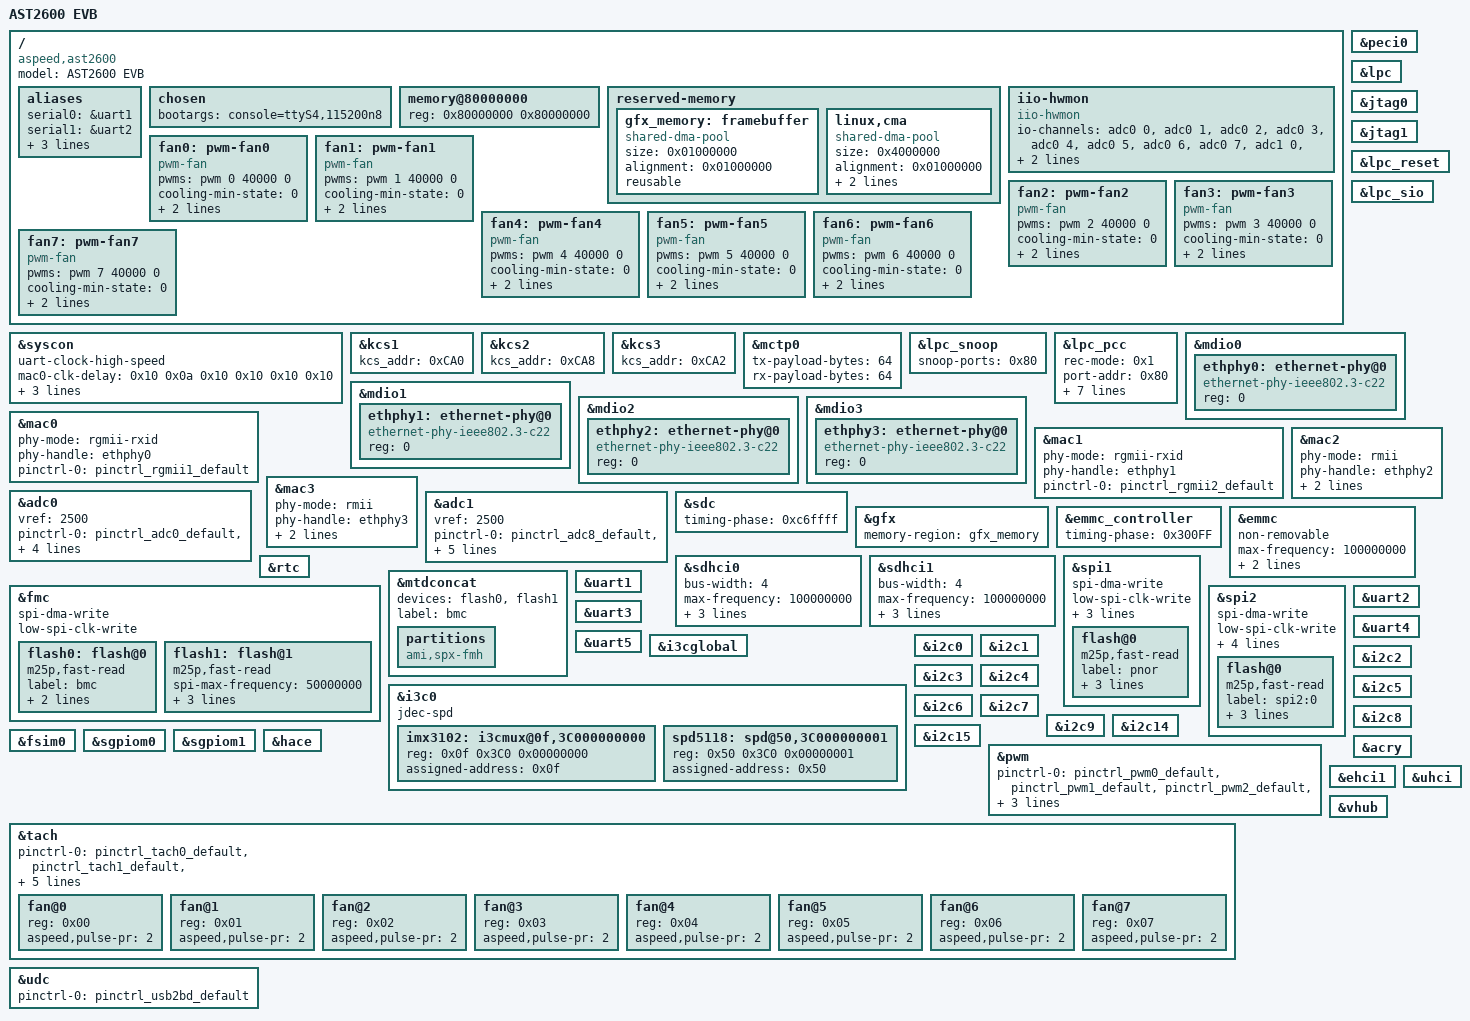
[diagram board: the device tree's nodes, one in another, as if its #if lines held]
// SPDX-License-Identifier: GPL-2.0-or-later
// Copyright 2019 IBM Corp.

/dts-v1/;

#include "aspeed-g6.dtsi"
#include <dt-bindings/gpio/aspeed-gpio.h>
#include <dt-bindings/i2c/i2c.h>
#include "../../../../../../include/projdef.h"

/ {
	model = "AST2600 EVB";
	compatible = "aspeed,ast2600";

	aliases {
		serial0 = &uart1;
		serial1 = &uart2;
		serial2 = &uart3;
		serial3 = &uart4;
		serial4 = &uart5;
	};

	chosen {
		bootargs = "console=ttyS4,115200n8";
	};

	memory@80000000 {
		device_type = "memory";
		reg = <0x80000000 0x80000000>;
	};
        reserved-memory {
                #address-cells = <1>;
                #size-cells = <1>;
                ranges;

                gfx_memory: framebuffer {
                        size = <0x01000000>;
                        alignment = <0x01000000>;
                        compatible = "shared-dma-pool";
                        reusable;
                };
#if defined(CONFIG_SPX_FEATURE_VIDEO_RVAS)
                linux,cma {
			            size = <0x4000000>; //64MB
			            alignment = <0x01000000>;
			            compatible = "shared-dma-pool";
			            reusable;
			            linux,cma-default;
                };
#endif				
         };



    iio-hwmon {
        compatible = "iio-hwmon";
        io-channels = <&adc0 0>, <&adc0 1>, <&adc0 2>, <&adc0 3>,
                        <&adc0 4>, <&adc0 5>, <&adc0 6>, <&adc0 7>,
                        <&adc1 0>, <&adc1 1>, <&adc1 2>, <&adc1 3>,
                        <&adc1 4>, <&adc1 5>, <&adc1 6>, <&adc1 7>;
    };

	fan0: pwm-fan0 {
		compatible = "pwm-fan";
		pwms = <&pwm 0 40000 0>;	/* Target freq:25 kHz */
		cooling-min-state = <0>;
		cooling-max-state = <3>;
		#cooling-cells = <2>;
		cooling-levels = <0 25 128 255>;
	};

	fan1: pwm-fan1 {
		compatible = "pwm-fan";
		pwms = <&pwm 1 40000 0>;	/* Target freq:25 kHz */
		cooling-min-state = <0>;
		cooling-max-state = <3>;
		#cooling-cells = <2>;
		cooling-levels = <0 15 128 255>;
	};

	fan2: pwm-fan2 {
		compatible = "pwm-fan";
		pwms = <&pwm 2 40000 0>;	/* Target freq:25 kHz */
		cooling-min-state = <0>;
		cooling-max-state = <3>;
		#cooling-cells = <2>;
		cooling-levels = <0 15 128 255>;
	};

	fan3: pwm-fan3 {
		compatible = "pwm-fan";
		pwms = <&pwm 3 40000 0>;	/* Target freq:25 kHz */
		cooling-min-state = <0>;
		cooling-max-state = <3>;
		#cooling-cells = <2>;
		cooling-levels = <0 15 128 255>;
	};

	fan4: pwm-fan4 {
		compatible = "pwm-fan";
		pwms = <&pwm 4 40000 0>;	/* Target freq:25 kHz */
		cooling-min-state = <0>;
		cooling-max-state = <3>;
		#cooling-cells = <2>;
		cooling-levels = <0 15 128 255>;
	};

	fan5: pwm-fan5 {
		compatible = "pwm-fan";
		pwms = <&pwm 5 40000 0>;	/* Target freq:25 kHz */
		cooling-min-state = <0>;
		cooling-max-state = <3>;
		#cooling-cells = <2>;
		cooling-levels = <0 15 128 255>;
	};

	fan6: pwm-fan6 {
		compatible = "pwm-fan";
		pwms = <&pwm 6 40000 0>;	/* Target freq:25 kHz */
		cooling-min-state = <0>;
		cooling-max-state = <3>;
		#cooling-cells = <2>;
		cooling-levels = <0 15 128 255>;
	};

	fan7: pwm-fan7 {
		compatible = "pwm-fan";
		pwms = <&pwm 7 40000 0>;	/* Target freq:25 kHz */
		cooling-min-state = <0>;
		cooling-max-state = <3>;
		#cooling-cells = <2>;
		cooling-levels = <0 15 128 255>;
	};
};

&syscon {
        uart-clock-high-speed;
        status = "okay";
		
		mac0-clk-delay = <0x10 0x0a
				  0x10 0x10
				  0x10 0x10>;
		mac1-clk-delay = <0x10 0x0a
				  0x10 0x10
				  0x10 0x10>;
		mac2-clk-delay = <0x08 0x04
				  0x08 0x04
				  0x08 0x04>;
		mac3-clk-delay = <0x08 0x04
				  0x08 0x04
				  0x08 0x04>;		
};

&kcs1 {
        kcs_addr = <0xCA0>;
        status = "okay";
};

&kcs2 {
        kcs_addr = <0xCA8>;
        status = "okay";
};

&kcs3 {
        kcs_addr = <0xCA2>;
        status = "okay";
};

&peci0 {
    status = "okay";
};

&lpc {
    status = "okay";
};

&jtag0 {
        status = "okay";
};

&jtag1 {
        status = "okay";
};

&mctp0 {
    tx-payload-bytes= <64>;
    rx-payload-bytes= <64>;
    status = "okay";
};

&lpc_reset {
        status = "okay";
};

&lpc_sio {
        status = "okay";
};

&lpc_snoop {
        snoop-ports = <0x80>;
        status = "okay";
};

&lpc_pcc { 
	rec-mode = <0x1>; 
	port-addr = <0x80>; 
	port-addr-hbits-select = <0x1>; 
	port-addr-xbits = <0x1>; 
	pattern-a-en; 
	pattern-a = <0x41424344>; 
	pattern-a-len = <0x4>; 
	pattern-a-write = <0x1>; 
	pattern-a-port = <0x80>; 
	status = "okay"; 
};

&mdio0 {
        status = "okay";

        ethphy0: ethernet-phy@0 {
                compatible = "ethernet-phy-ieee802.3-c22";
                reg = <0>;
        };
};

&mdio1 {
	status = "okay";

	ethphy1: ethernet-phy@0 {
		compatible = "ethernet-phy-ieee802.3-c22";
		reg = <0>;
	};
};

&mdio2 {
	status = "okay";

	ethphy2: ethernet-phy@0 {
		compatible = "ethernet-phy-ieee802.3-c22";
		reg = <0>;
	};
};

&mdio3 {
	status = "okay";

	ethphy3: ethernet-phy@0 {
		compatible = "ethernet-phy-ieee802.3-c22";
		reg = <0>;
	};
};

&mac0 {
        status = "okay";

        phy-mode = "rgmii-rxid";
        phy-handle = <&ethphy0>;

        pinctrl-names = "default";
        pinctrl-0 = <&pinctrl_rgmii1_default>;
};

&mac1 {
	status = "okay";

	phy-mode = "rgmii-rxid";
	phy-handle = <&ethphy1>;

	pinctrl-names = "default";
	pinctrl-0 = <&pinctrl_rgmii2_default>;
};

#ifdef CONFIG_SPX_FEATURE_NCSI_ACTIVE_MAC3
&mac2 {
	status = "okay";

	phy-mode = "rmii";
	phy-handle = <&ethphy2>;
	use-ncsi;
	
	pinctrl-names = "default";
	pinctrl-0 = <&pinctrl_rmii3_default>;
};
#else
&mac2 {
	status = "okay";

	phy-mode = "rgmii";
	phy-handle = <&ethphy2>;
	
	pinctrl-names = "default";
	pinctrl-0 = <&pinctrl_rgmii3_default>;
};
#endif

#ifdef CONFIG_SPX_FEATURE_NCSI_ACTIVE_MAC4
&mac3 {
	status = "okay";

	phy-mode = "rmii";
	phy-handle = <&ethphy3>;
	use-ncsi;
	
	pinctrl-names = "default";
	pinctrl-0 = <&pinctrl_rmii4_default>;
};
#else
&mac3 {
	status = "okay";

	phy-mode = "rgmii";
	phy-handle = <&ethphy3>;

	pinctrl-names = "default";
	pinctrl-0 = <&pinctrl_rgmii4_default>;
};
#endif

&adc0 {
	vref = <2500>;
	status = "okay";

	pinctrl-names = "default";
	pinctrl-0 = <&pinctrl_adc0_default &pinctrl_adc1_default
		&pinctrl_adc2_default &pinctrl_adc3_default
		&pinctrl_adc4_default &pinctrl_adc5_default
		&pinctrl_adc6_default &pinctrl_adc7_default>;
};

&adc1 {
	vref = <2500>;
	status = "okay";

	pinctrl-names = "default";
	pinctrl-0 = <&pinctrl_adc8_default &pinctrl_adc9_default
		&pinctrl_adc10_default &pinctrl_adc11_default
		&pinctrl_adc12_default &pinctrl_adc13_default
		&pinctrl_adc14_default &pinctrl_adc15_default>;
};

&sdc {
	status = "okay";	
};

&gfx {
        status = "okay";
        memory-region = <&gfx_memory>;
};

&emmc_controller {
	status = "okay";
	timing-phase = <0x300FF>;
};

&emmc {
    status = "okay";
    non-removable;
    max-frequency = <100000000>;
    sdhci-drive-type = /bits/ 8 <3>;
#if 1
    bus-width = <4>;
#else
    bus-width = <8>;
    pinctrl-0 = <&pinctrl_emmc_default
            &pinctrl_emmcg8_default>;
#endif

};

&sdc {
	status = "okay";
	timing-phase = <0xc6ffff>;
};

&sdhci0 {
    status = "okay";
    bus-width = <4>;
    max-frequency = <100000000>;
    sdhci-drive-type = /bits/ 8 <3>;
    /* SDR104/DDR50/SDR50 bits in CAPA2 is not supported */
    sdhci-caps-mask = <0x7 0x580000>;
    sdhci,wp-inverted;
};

&sdhci1 {
    status = "okay";
    bus-width = <4>;
    max-frequency = <100000000>;
    sdhci-drive-type = /bits/ 8 <3>;
    sdhci-caps-mask = <0x7 0x580000>;
    sdhci,wp-inverted;
};

&rtc {
	status = "okay";
};

&fmc {
	spi-dma-write;
	low-spi-clk-write;
	status = "okay";
	flash0:flash@0 {
		status = "okay";
		m25p,fast-read;
		label = "bmc";
		spi-max-frequency = <50000000>;
#ifdef CONFIG_SPX_FEATURE_DEDICATED_SPI_FLASH_BANK
		reg = <0>;
#else		
	        partitions {
	            compatible = "ami,spx-fmh";
	        };
#endif	
	};
	flash1:flash@1 {
		status = "okay";
		m25p,fast-read;
		spi-max-frequency = <50000000>;
		spi-bus-width = <4>;
#ifdef CONFIG_SPX_FEATURE_DEDICATED_SPI_FLASH_BANK
		label = "bmc";
		reg = <1>;
#else
		label = "fmc0:1";
#endif				
	};
};
#ifdef CONFIG_SPX_FEATURE_DEDICATED_SPI_FLASH_BANK
&mtdconcat {
	status="okay";
	devices=<&flash0 &flash1>;
 	label = "bmc";
	partitions {
           compatible = "ami,spx-fmh";
	};

};
#endif
&spi1 {
        spi-dma-write;
        low-spi-clk-write;
	pinctrl-names = "default";
	pinctrl-0 = <&pinctrl_spi1_default &pinctrl_spi1cs1_default
				&pinctrl_qspi1_default>;
	status = "okay";

	flash@0 {
		status = "okay";
		m25p,fast-read;
		label = "pnor";
		spi-max-frequency = <50000000>;
		spi-tx-bus-width = <4>;
		spi-rx-bus-width = <4>;		
	};
};


&spi2 {
        spi-dma-write;
        low-spi-clk-write;
	pinctrl-names = "default";
	pinctrl-0 = <&pinctrl_spi2_default &pinctrl_spi2cs1_default
				&pinctrl_spi2cs2_default &pinctrl_qspi2_default>;
	status = "okay";

	flash@0 {
		status = "okay";
		m25p,fast-read;
		label = "spi2:0";
		spi-max-frequency = <50000000>;
		spi-tx-bus-width = <4>;
		spi-rx-bus-width = <4>;
	};
};
&uart1 {
	status = "okay";
};

&uart2 {
	status = "okay";
};

&uart3 {
	status = "okay";
};

&uart4 {
	status = "okay";
};

&uart5 {
	status = "okay";
};

&i3cglobal {
	status = "okay";
};
&i3c0 {
        status = "okay";
        jdec-spd;
        /* IDT IMX3102 multiplexer w/ thermal sensor */
        imx3102: i3cmux@0f,3C000000000 {
                reg = <0x0f 0x3C0 0x00000000>;
                assigned-address = <0x0f>;
        };

        /* Renesas SPD5118 */
        spd5118: spd@50,3C000000001 {
                reg = <0x50 0x3C0 0x00000001>;
                assigned-address = <0x50>;
        };
};

&i2c0 {
	status = "okay";
};

&i2c1 {
	status = "okay";
};

&i2c2 {
	status = "okay";
};

&i2c3 {
	status = "okay";
};

&i2c4 {
	status = "okay";
};

&i2c5 {
	status = "okay";
};

&i2c6 {
	status = "okay";
};

&i2c7 {
	status = "okay";
};

&i2c8 {
	status = "okay";
};

&i2c9 {
	status = "okay";
};

&i2c14 {
	status = "okay";
};

&i2c15 {
	status = "okay";
};

&fsim0 {
	status = "okay";
};
&sgpiom0 {
        status = "okay";
};
&sgpiom1 { 
	status = "okay"; 
}; 

&hace {
        status = "okay";
};

&acry {
        status = "okay";
};

&pwm {
	status = "okay";
	pinctrl-names = "default";
	pinctrl-0 = <&pinctrl_pwm0_default
			&pinctrl_pwm1_default
			&pinctrl_pwm2_default
			&pinctrl_pwm3_default
			&pinctrl_pwm4_default
			&pinctrl_pwm5_default
			&pinctrl_pwm6_default
			&pinctrl_pwm7_default>;
};

&tach {
	status = "okay";
	pinctrl-names = "default";
	pinctrl-0 = <&pinctrl_tach0_default
			&pinctrl_tach1_default
			&pinctrl_tach2_default
			&pinctrl_tach3_default
			&pinctrl_tach4_default
			&pinctrl_tach5_default
			&pinctrl_tach6_default
			&pinctrl_tach7_default>;
	fan@0 {
		reg = <0x00>;
		aspeed,pulse-pr = <2>;
	};

	fan@1 {
		reg = <0x01>;
		aspeed,pulse-pr = <2>;
	};

	fan@2 {
		reg = <0x02>;
		aspeed,pulse-pr = <2>;
	};

	fan@3 {
		reg = <0x03>;
		aspeed,pulse-pr = <2>;
	};

	fan@4 {
		reg = <0x04>;
		aspeed,pulse-pr = <2>;
	};

	fan@5 {
		reg = <0x05>;
		aspeed,pulse-pr = <2>;
	};

	fan@6 {
		reg = <0x06>;
		aspeed,pulse-pr = <2>;
	};

	fan@7 {
		reg = <0x07>;
		aspeed,pulse-pr = <2>;
	};
};

#ifdef CONFIG_SPX_FEATURE_USB_PORT_B_HOST_SUPPORT
&ehci1 {
	status = "okay";
};

&uhci {
	status = "okay";
};
#endif

&vhub {
        status = "okay";
};

#ifdef CONFIG_SPX_FEATURE_USB_PORT_B_SUPPORT
&udc {
        status = "okay";
        pinctrl-names = "default";
        pinctrl-0 = <&pinctrl_usb2bd_default>;
};
#endif

#include "legacy.dtsi" /* For Legacy AMI Drivers */

